# ipro7 register map
Vendor: intelpro; Series: BTBLE
CPU: ipro7, little endian
Registers are 32-bit, read-write, reset 0x0 unless marked. A register's access mark holds for its fields unless they carry their own. Offsets are from the block's base; [hi:lo] are bit positions; lines under a group give offsets from that group; {n}, {i} and the like mark numbered series; <NAME> marks a mode.

## M154
Base 0x3C000000
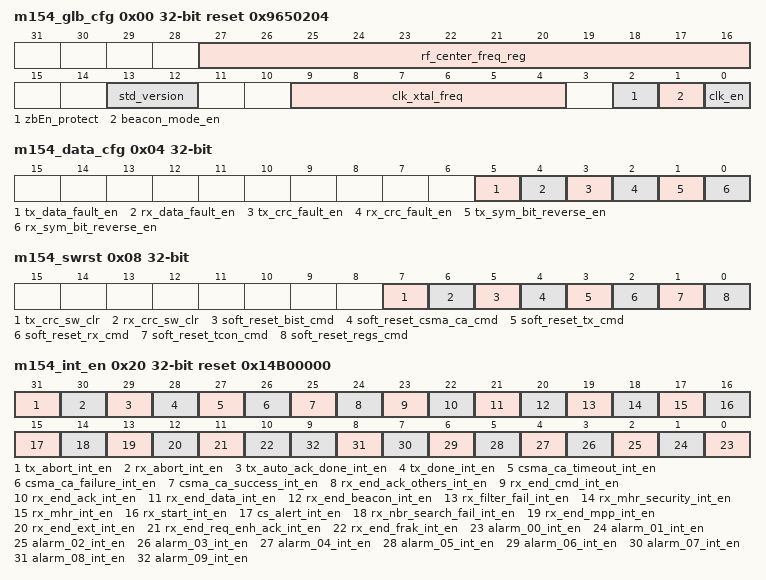
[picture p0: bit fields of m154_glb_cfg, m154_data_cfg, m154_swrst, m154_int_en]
0x00 m154_glb_cfg reset 0x9650204
  [27:16] rf_center_freq_reg — Clock frequency (MHz)
  [13:12] std_version — 0: 802.15.4-2011 and before 1: 802.15.4-2015 others: reserved
  [9:4] clk_xtal_freq — Clock frequency (MHz)
  [2] zbEn_protect — If protect, when zbEn=0, MAC enter idle state
  [1] beacon_mode_en — Beacon enable
  [0] clk_en — MAC enable
0x04 m154_data_cfg
  [5] tx_data_fault_en — Insert fault to TX data by inverting all bits
  [4] rx_data_fault_en — Insert fault to RX data by inverting all bits
  [3] tx_crc_fault_en — Insert fault to TX FCS by inverting all bits
  [2] rx_crc_fault_en — Insert fault to RX FCS by inverting all bits
  [1] tx_sym_bit_reverse_en — Swap TX symbol bit order
  [0] rx_sym_bit_reverse_en — Swap RX symbol bit order
0x08 m154_swrst
  [7] tx_crc_sw_clr — SW clear TX CRC state registers.
  [6] rx_crc_sw_clr — SW clear RX CRC state registers.
  [5] soft_reset_bist_cmd — SW reset BIST
  [4] soft_reset_csma_ca_cmd — SW reset TX CSMA-CA
  [3] soft_reset_tx_cmd — SW reset TX
  [2] soft_reset_rx_cmd — SW reset RX
  [1] soft_reset_tcon_cmd — SW reset symbol counter and timing controller
  [0] soft_reset_regs_cmd — SW reset control registers
0x0C m154_dbg_sel
  [3:0] debug_out_sel
0x10 m154_dbg_int_en
  [31:0] debug_int_raw_en
0x20 m154_int_en reset 0x14B00000
  [31] tx_abort_int_en — TX abort interrupt enable
  [30] rx_abort_int_en — RX abort interrupt enable
  [29] tx_auto_ack_done_int_en — TX auto ACK frame transmission done interrupt enable
  [28] tx_done_int_en — TX done interrupt enable
  [27] csma_ca_timeout_int_en — CSMA-CA time out interrupt enable
  [26] csma_ca_failure_int_en — CSMA-CA failure interrupt enable
  [25] csma_ca_success_int_en — CSMA-CA success interrupt enable
  [24] rx_end_ack_others_int_en — RX end of irrelevant ACK frame (to other devices) interrupt enable
  [23] rx_end_cmd_int_en — RX end of COMMAND frame interrupt enable
  [22] rx_end_ack_int_en — RX end of relevant ACK frame (to this device) interrupt enable
  [21] rx_end_data_int_en — RX end of DATA frame interrupt enable
  [20] rx_end_beacon_int_en — RX end of BEACON frame interrupt enable
  [19] rx_filter_fail_int_en — RX filtering fail interrupt enable
  [18] rx_mhr_security_int_en — RX MAC header (with security enable field as TRUE) interrupt enable
  [17] rx_mhr_int_en — RX MAC header (regardless of security field) interrupt enable
  [16] rx_start_int_en — RX start interrupt enable
  [15] cs_alert_int_en — 802.15.4 context switch alert interrupt enable
  [14] rx_nbr_search_fail_int_en — RX NBR search fail interrupt enable.
  [13] rx_end_mpp_int_en — RX end of relevant MULTI PURPOSE frame (to this device) interrupt enable
  [12] rx_end_ext_int_en — RX end of relevant EXTENDED frame (to this device) interrupt enable
  [11] rx_end_req_enh_ack_int_en — RX end of requesting Enh-Ack frame interrupt enable
  [10] rx_end_frak_int_en — RX end of relevant FRAGEMENT or FRAK frame (to this device) interrupt enable
  [n] alarm_{n:02}_int_en (n=0..9) — Alarm {n:02} interrupt enable
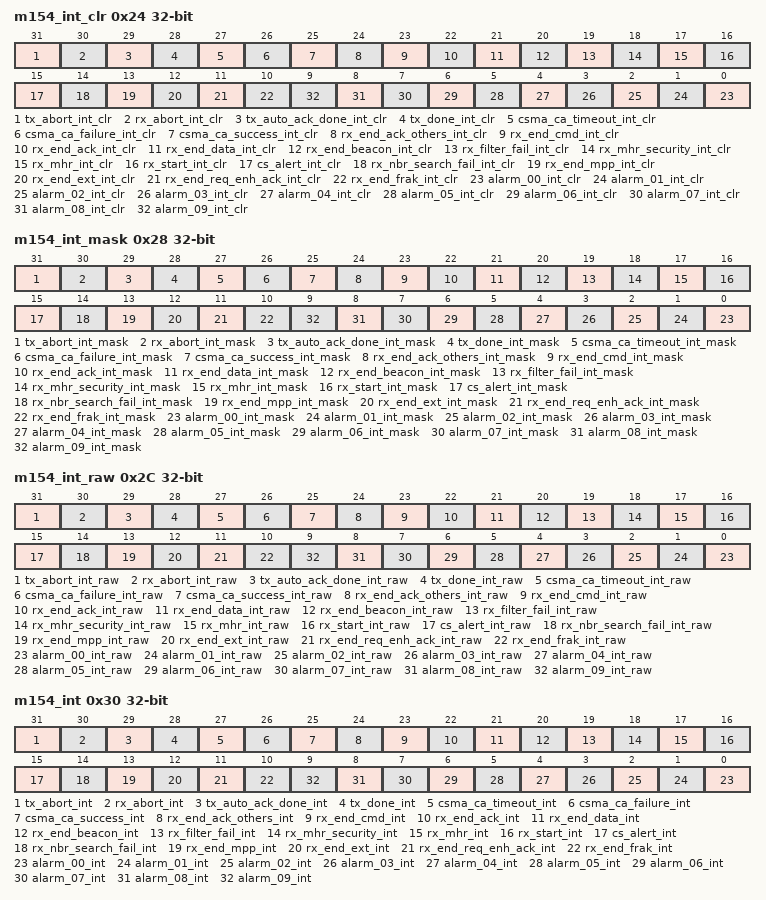
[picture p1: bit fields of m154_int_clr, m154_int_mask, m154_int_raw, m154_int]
0x24 m154_int_clr
  [31] tx_abort_int_clr — TX abort interrupt clear
  [30] rx_abort_int_clr — RX abort interrupt clear
  [29] tx_auto_ack_done_int_clr — TX auto ACK frame transmission done interrupt clear. Set to let TX FSM escape from FSM_AA_DONE
  [28] tx_done_int_clr — TX done interrupt clear. Set to let TX FSM escape from FSM_DONE
  [27] csma_ca_timeout_int_clr — CSMA-CA time out interrupt clear
  [26] csma_ca_failure_int_clr — CSMA-CA failure interrupt clear
  [25] csma_ca_success_int_clr — CSMA-CA success interrupt clear
  [24] rx_end_ack_others_int_clr — RX end of irrelevant ACK frame (to other devices) interrupt clear
  [23] rx_end_cmd_int_clr — RX end of COMMAND frame interrupt clear
  [22] rx_end_ack_int_clr — RX end of relevant ACK frame (to this device) interrupt clear
  [21] rx_end_data_int_clr — RX end of DATA frame interrupt clear
  [20] rx_end_beacon_int_clr — RX end of BEACON frame interrupt clear
  [19] rx_filter_fail_int_clr — RX filtering fail interrupt clear
  [18] rx_mhr_security_int_clr — RX MAC header (with security enable field as TRUE) interrupt clear
  [17] rx_mhr_int_clr — RX MAC header (regardless of security field) interrupt clear
  [16] rx_start_int_clr — RX start interrupt clear
  [15] cs_alert_int_clr — 802.15.4 context switch alert interrupt clear
  [14] rx_nbr_search_fail_int_clr — RX NBR search fail interrupt clear
  [13] rx_end_mpp_int_clr — RX end of relevant MULTI PURPOSE frame (to this device) interrupt clear
  [12] rx_end_ext_int_clr — RX end of relevant EXTENDED frame (to this device) interrupt clear
  [11] rx_end_req_enh_ack_int_clr — RX end of requesting Enh-Ack frame interrupt clear
  [10] rx_end_frak_int_clr — RX end of relevant FRAGEMENT or FRAK frame (to this device) interrupt clear
  [n] alarm_{n:02}_int_clr (n=0..9) — Alarm {n:02} interrupt clear
0x28 m154_int_mask
  [31] tx_abort_int_mask — TX abort interrupt mask
  [30] rx_abort_int_mask — RX abort interrupt mask
  [29] tx_auto_ack_done_int_mask — TX auto ACK frame transmission done interrupt mask
  [28] tx_done_int_mask — TX done interrupt mask
  [27] csma_ca_timeout_int_mask — CSMA-CA time out interrupt mask
  [26] csma_ca_failure_int_mask — CSMA-CA failure interrupt mask
  [25] csma_ca_success_int_mask — CSMA-CA success interrupt mask
  [24] rx_end_ack_others_int_mask — RX end of irrelevant ACK frame (to other devices) interrupt mask
  [23] rx_end_cmd_int_mask — RX end of COMMAND frame interrupt mask
  [22] rx_end_ack_int_mask — RX end of relevant ACK frame (to this device) interrupt mask
  [21] rx_end_data_int_mask — RX end of DATA frame interrupt mask
  [20] rx_end_beacon_int_mask — RX end of BEACON frame interrupt mask
  [19] rx_filter_fail_int_mask — RX filtering fail interrupt mask
  [18] rx_mhr_security_int_mask — RX MAC header (with security enable field as TRUE) interrupt mask
  [17] rx_mhr_int_mask — RX MAC header (regardless of security field) interrupt mask
  [16] rx_start_int_mask — RX start interrupt mask
  [15] cs_alert_int_mask — 802.15.4 context switch alert interrupt mask
  [14] rx_nbr_search_fail_int_mask — RX NBR search fail interrupt mask
  [13] rx_end_mpp_int_mask — RX end of relevant MULTI PURPOSE frame (to this device) interrupt mask
  [12] rx_end_ext_int_mask — RX end of relevant EXTEND frame (to this device) interrupt mask
  [11] rx_end_req_enh_ack_int_mask — RX end of requesting Enh-Ack frame interrupt mask
  [10] rx_end_frak_int_mask — RX end of relevant FRAGEMENT or FRAK frame (to this device) interrupt mask
  [n] alarm_{n:02}_int_mask (n=0..9) — Alarm {n:02} interrupt mask
0x2C m154_int_raw reset not defined
  [31] tx_abort_int_raw ro — TX abort interrupt raw status
  [30] rx_abort_int_raw ro — RX abort interrupt raw status
  [29] tx_auto_ack_done_int_raw ro — TX auto ACK frame transmission done interrupt raw status
  [28] tx_done_int_raw ro — TX done interrupt raw status
  [27] csma_ca_timeout_int_raw ro — CSMA-CA time out interrupt raw status
  [26] csma_ca_failure_int_raw ro — CSMA-CA failure interrupt raw status
  [25] csma_ca_success_int_raw ro — CSMA-CA success interrupt raw status
  [24] rx_end_ack_others_int_raw ro — RX end of irrelevant ACK frame (to other devices) interrupt raw status
  [23] rx_end_cmd_int_raw ro — RX end of COMMAND frame interrupt raw status
  [22] rx_end_ack_int_raw ro — RX end of relevant ACK frame (to this device) interrupt raw status
  [21] rx_end_data_int_raw ro — RX end of DATA frame interrupt raw status
  [20] rx_end_beacon_int_raw ro — RX end of BEACON frame interrupt raw status
  [19] rx_filter_fail_int_raw ro — RX filtering fail interrupt raw status
  [18] rx_mhr_security_int_raw ro — RX MAC header (with security enable field as TRUE) interrupt raw status (Not for ACK frames)
  [17] rx_mhr_int_raw ro — RX MAC header (regardless of security field) interrupt raw status (Not for ACK frames)
  [16] rx_start_int_raw ro — RX start interrupt raw status
  [15] cs_alert_int_raw ro — 802.15.4 context switch alert interrupt raw status. To detect if 802.15.4 MAC is doing TX/RX when zbEn=0
  [14] rx_nbr_search_fail_int_raw ro — RX NBR search fail interrupt raw status. This is an indication that data request command frame is received but source address is not found in NBR list.
  [13] rx_end_mpp_int_raw ro — RX end of relevant MULTI PURPOSE frame (to this device) interrupt raw status
  [12] rx_end_ext_int_raw ro — RX end of relevant EXTENDED frame (to this device) interrupt raw status
  [11] rx_end_req_enh_ack_int_raw ro — RX end of requesting Enh-Ack frame interrupt status
  [10] rx_end_frak_int_raw ro — RX end of relevant FRAGEMENT or FRAK frame (to this device) interrupt raw status
  [n] alarm_{n:02}_int_raw ro (n=0..9) — Alarm {n:02} interrupt raw status
0x30 m154_int reset not defined
  [31] tx_abort_int ro — TX abort interrupt after masking
  [30] rx_abort_int ro — RX abort interrupt after masking
  [29] tx_auto_ack_done_int ro — TX auto ACK frame transmission done interrupt after masking
  [28] tx_done_int ro — TX done interrupt after masking
  [27] csma_ca_timeout_int ro — CSMA-CA time out interrupt after masking
  [26] csma_ca_failure_int ro — CSMA-CA failure interrupt after masking
  [25] csma_ca_success_int ro — CSMA-CA success interrupt after masking
  [24] rx_end_ack_others_int ro — RX end of irrelevant ACK frame (to other devices) interrupt after masking
  [23] rx_end_cmd_int ro — RX end of COMMAND frame interrupt after masking
  [22] rx_end_ack_int ro — RX end of relevant ACK frame (to this device) interrupt after masking
  [21] rx_end_data_int ro — RX end of DATA frame interrupt after masking
  [20] rx_end_beacon_int ro — RX end of BEACON frame interrupt after masking
  [19] rx_filter_fail_int ro — RX filtering fail interrupt after masking
  [18] rx_mhr_security_int ro — RX MAC header (with security enable field as TRUE) interrupt after masking (Not for ACK frames)
  [17] rx_mhr_int ro — RX MAC header (regardless of security field) interrupt after masking (Not for ACK frames)
  [16] rx_start_int ro — RX start interrupt after masking
  [15] cs_alert_int ro — 802.15.4 context switch alert interrupt after masking
  [14] rx_nbr_search_fail_int ro — RX NBR search fail interrupt after masking. This is an indication that data request command frame is received but source address is not found in NBR list.
  [13] rx_end_mpp_int ro — RX end of relevant MULTI PURPOSE frame (to this device) interrupt after masking.
  [12] rx_end_ext_int ro — RX end of relevant EXTENDED frame (to this device) interrupt after masking.
  [11] rx_end_req_enh_ack_int ro — RX end of requesting Enh-Ack frame interrupt masking
  [10] rx_end_frak_int ro — RX end of relevant FRAGEMENT or FRAK frame (to this device) interrupt after masking.
  [n] alarm_{n:02}_int ro (n=0..9) — Alarm {n:02} interrupt after masking
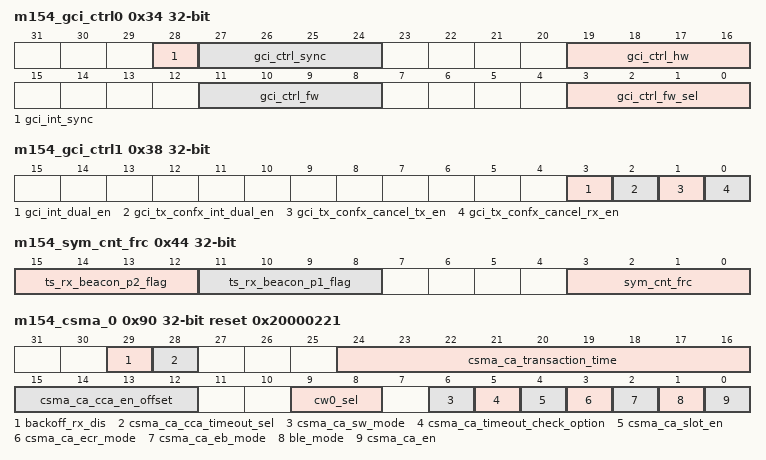
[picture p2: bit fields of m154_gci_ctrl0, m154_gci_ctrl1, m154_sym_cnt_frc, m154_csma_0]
0x34 m154_gci_ctrl0 (reset mask 0xE0F0FFFF)
  [28] gci_int_sync ro — Interrupt from GCI
  [27:24] gci_ctrl_sync ro — Control signals from GCI
  [19:16] gci_ctrl_hw ro — Hardware mode control signals to GCI [2] RX in process [1] STATUS [0] RF_ACTIVE
  [11:8] gci_ctrl_fw — Firmware mode control signals to GCI
  [3:0] gci_ctrl_fw_sel — Select control signals to GCI. 0: 2_gci_ctrl_hw, 1: 2_gci_ctrl_fw
0x38 m154_gci_ctrl1
  [3] gci_int_dual_en — Assert gci_int_raw by both edges of f_gci_int_sync
  [2] gci_tx_confx_int_dual_en — Assert gci_tx_confx_int_raw by both edges of f_gci_ctrl_sync[0]
  [1] gci_tx_confx_cancel_tx_en — Cancel TX by f_gci_ctrl_sync[0]
  [0] gci_tx_confx_cancel_rx_en — Cancel RX by f_gci_ctrl_sync[0]
0x40 m154_sym_cnt reset not defined
  [31:0] sym_cnt ro — Free run symbol counter. Increase every 16 us.
0x44 m154_sym_cnt_frc (reset mask 0xFFFF00F0)
  [15:12] ts_rx_beacon_p2_flag ro — Flags for RX BEACON frame at ts_rx_beacon_p2 bit 0: PAN ID == rx_pan_id_1st && rx_stack_1st_en == 1 bit 1: PAN ID == 16'hFFFF && rx_stack_1st_en == 1 bit 2: PAN ID == rx_pan_id_2nd && rx_stack_2nd_en == 1 bit 3: PAN ID == 16'hFFFF && rx_stack_2nd_en == 1
  [11:8] ts_rx_beacon_p1_flag ro — Flags for RX BEACON frame at ts_rx_beacon_p1 bit 0: PAN ID == rx_pan_id_1st && rx_stack_1st_en == 1 bit 1: PAN ID == 16'hFFFF && rx_stack_1st_en == 1 bit 2: PAN ID == rx_pan_id_2nd && rx_stack_2nd_en == 1 bit 3: PAN ID == 16'hFFFF && rx_stack_2nd_en == 1
  [3:0] sym_cnt_frc ro — Fractional part of free run symbol counter. Increase every 1 us.
0x48 m154_ts_rx_beacon_p1 reset not defined
  [31:0] ts_rx_beacon_p1 ro — Timestamp(us) at the latest RX BEACON frame
0x4C m154_ts_rx_beacon_p2 reset not defined
  [31:0] ts_rx_beacon_p2 ro — Timestamp(us) at RX BEACON frame prior to the latest RX BEACON frame
0x50 m154_ts_rx_start reset not defined
  [31:0] ts_rx_start ro — Timestamp(us) at start of receiving
0x54 m154_ts_rx_end reset not defined
  [31:0] ts_rx_end ro — Timestamp(us) at end of receiving
0x58 m154_ts_csma_ca_start reset not defined
  [31:0] ts_csma_ca_start ro — Timestamp(us) at start of CSMA-CA
0x5C m154_ts_tx_beacon reset not defined
  [31:0] ts_tx_beacon ro — Timestamp(us) at the latest TX BEACON frame
0x60 m154_ts_tx_end reset not defined
  [31:0] ts_tx_end ro — Timestamp(us) at end of transmitting
0x64 m154_alarm_00_target reset 0x10
  [31:0] alarm_00_target — Alarm 00 target value of symbol counter. Interrupt asserted @this symbol time
0x68 m154_alarm_01_target reset 0x20
  [31:0] alarm_01_target — Alarm 01 target value of symbol counter. Interrupt asserted @this symbol time
0x6C m154_alarm_02_target reset 0x30
  [31:0] alarm_02_target — Alarm 02 target value of symbol counter. Interrupt asserted @this symbol time
0x70 m154_alarm_03_target reset 0x40
  [31:0] alarm_03_target — Alarm 03 target value of symbol counter. Interrupt asserted @this symbol time
0x74 m154_alarm_04_target reset 0x50
  [31:0] alarm_04_target — Alarm 04 target value of symbol counter. Interrupt asserted @this symbol time
0x78 m154_alarm_05_target reset 0x60
  [31:0] alarm_05_target — Alarm 05 target value of symbol counter. Interrupt asserted @this symbol time
0x7C m154_alarm_06_target reset 0x70
  [31:0] alarm_06_target — Alarm 06 target value of symbol counter. Interrupt asserted @this symbol time
0x80 m154_alarm_07_target reset 0x80
  [31:0] alarm_07_target — Alarm 07 target value of symbol counter. Interrupt asserted @this symbol time
0x84 m154_alarm_08_target reset 0x90
  [31:0] alarm_08_target — Alarm 08 target value of symbol counter. Interrupt asserted @this symbol time
0x88 m154_alarm_09_target reset 0xA0
  [31:0] alarm_09_target — Alarm 09 target value of symbol counter. Interrupt asserted @this symbol time
0x90 m154_csma_0 reset 0x20000221
  [29] backoff_rx_dis — Disable packet receipt in Backoff state.
  [28] csma_ca_cca_timeout_sel — CCA timeout selection: 20 or 40 symbol periods. If timeout, csma_ca_timeout_int_raw = 1
  [24:16] csma_ca_transaction_time — Transaction time (SHR+PHR+PSDU). If need ACK, include macAckWaitDuration (54 symbol periods)
  [15:12] csma_ca_cca_en_offset — CCA trigger 8*N us earlier than next backoff boundary
  [9:8] cw0_sel — Initial CW (Contention Window) length setting. Set 1 for Japanese 950MHz band. Set 2 for others
  [6] csma_ca_sw_mode
  [5] csma_ca_timeout_check_option — CSMA-CA timeout check option 0: Detect PHY CCA no respond only. When csma_ca_timeout_int_raw = 1, it's CCA timeout 1: Detect PHY CCA no respond or TX cannot complete in CAP. When csma_ca_timeout_int_raw = 1, FW need to check csma_ca_fsm_curr : st_timeout_cca (CCA timeout) or st_timeout (TX cannot complete in CAP)
  [4] csma_ca_slot_en — Slotted enable
  [3] csma_ca_ecr_mode — Enhanced collision resolution mode
  [2] csma_ca_eb_mode — Enhanced backoff mode
  [1] ble_mode — Battery life extension mode
  [0] csma_ca_en — CSMA-CA is required before transmission
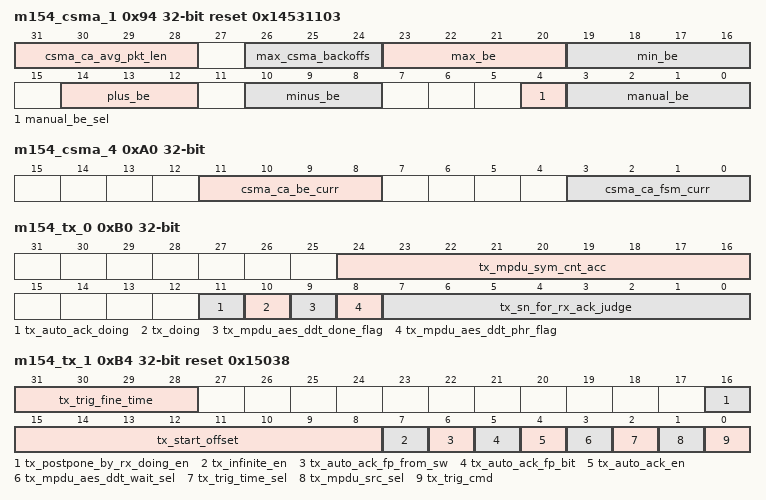
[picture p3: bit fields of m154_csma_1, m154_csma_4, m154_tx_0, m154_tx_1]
0x94 m154_csma_1 reset 0x14531103
  [31:28] csma_ca_avg_pkt_len — Average packet length = SHR(5B) + PHR(1B) + Average pay load (5~127 bytes)
  [26:24] max_csma_backoffs — Max number of CSMA-CA backoff before declaring a channel access failure. Range=0~5
  [23:20] max_be — Max value of CSMA-CA BE (Backoff Exponent). Range=3~8
  [19:16] min_be — Min value of CSMA-CA BE (Backoff Exponent). Range=0~max_be
  [14:12] plus_be — BE is increased by plus_be after failure of CSMA-CA @csma_ca_ecr_mode = 1
  [10:8] minus_be — BE is decreased by minus_be after success of CSMA-CA @csma_ca_ecr_mode = 1
  [4] manual_be_sel — BE manual enable
  [3:0] manual_be — BE fixed this value @manual_be_sel = 1 Used to init preBE @csma_ca_ecr_mode = 1
0x98 m154_csma_2
  [31:0] csma_ca_cap_end — Symbol time of CAP end
0x9C m154_csma_3
  [31:0] csma_ca_ble_period_end — Symbol time of BLE (Battery Life Extension) period end
0xA0 m154_csma_4 (reset mask 0xFFFFF0F0)
  [11:8] csma_ca_be_curr ro — Current BE value. FW need to check after finishing CSMA-CA for ECR mode
  [3:0] csma_ca_fsm_curr ro — CSMA-CA FSM 0: st_idle. 1: st_load_setting1. Load random generator seed 2: st_load_setting2. Generate random data 3: st_timeout_check. Check sufficient time to transmit 4: st_bp_delay. BP (Backoff Period) random delay 5: st_cca1. Perform 1st CCA 6: st_cca2. Perform 2nd CCA 7: st_cca3. Perform 3rd CCA 8: st_failure_check. Check NB value. 9: st_timeout_cca. Interrupt timeout 10: st_success. Interrupt success 11: st_failure. Interrupt fail 12: st_timeout. Interrupt timeout
0xB0 m154_tx_0 (reset mask 0xFE00F000)
  [24:16] tx_mpdu_sym_cnt_acc ro — Symbol sent count of the current frame
  [11] tx_auto_ack_doing ro — TX auto ACK in-progress (wait SIFS, send MAC frame)
  [10] tx_doing ro — TX transmission in-progress (wait AES TX DDT, run CSMA-CA, wait BP boundary, wait PHY on, send MAC frame)
  [9] tx_mpdu_aes_ddt_done_flag ro — AES TX DDT done
  [8] tx_mpdu_aes_ddt_phr_flag ro — AES TX DDT tx_phr written
  [7:0] tx_sn_for_rx_ack_judge ro — SN (Sequence Number) of data/command frame
0xB4 m154_tx_1 reset 0x15038
  [31:28] tx_trig_fine_time — If csma_ca_en = 0, the time preamble is transmitted. If csma_ca_en = 1, TX delay fine time(0~15 us) after tx_trig_cmd = 1.
  [16] tx_postpone_by_rx_doing_en — Wait rx_doing = 0 before TX start
  [15:8] tx_start_offset — PHY/RF warm-up time (us)
  [7] tx_infinite_en — Continuus TX with PRBS15 pattern till this bit is reset to 0 by SW. PHR field of TX packet will be 0 if this bit is set to 1.
  [6] tx_auto_ack_fp_from_sw — If this bit is set to 1, frame pending bit in TX Auto Ack frame is equal to tx_auto_ack_fp_bit. Otherwise, frame pending bit in TX Auto Ack frame is determined by result of NBR search.
  [5] tx_auto_ack_fp_bit — Frame Pending bit when TX auto ACK is enabled. If enable, Frame Pending bit is set to 1 when Rx Frame Type == 3'b011 and Command Frame Identifier == 8'h4, set to 0 for other cases
  [4] tx_auto_ack_en — Auto ACK enable
  [3] tx_mpdu_aes_ddt_wait_sel — Wait tx_mpdu_aes_ddt_done @ tx_mpdu_src_sel = 1 0: TX trigger after AES TX DDT writes PHR 1: TX trigger after tx_mpdu_aes_ddt_done
  [2] tx_trig_time_sel — TX trigger time @ tx_trg_cmd = 1 If tx_mpdu_src_sel = 0 0: immediately 1: after sym_cnt exceeds tx_trig_time If tx_mpdu_src_sel = 1 && tx_mpdu_aes_ddt_wait_sel = 0 0: after AES TX DDT writes PHR 1: after AES TX DDT writes PHR and sym_cnt exceeds tx_trig_time If tx_mpdu_src_sel = 1 && tx_mpdu_aes_ddt_wait_sel = 1 0: after AES TX DDT is done 1: after AES TX DDT is done and sym_cnt exceeds tx_trig_time
  [1] tx_mpdu_src_sel — TX MPDU source. 0: FW (AHB), 1: DDT (internal)
  [0] tx_trig_cmd — TX start
0xB8 m154_tx_2
  [31:0] tx_trig_time — If csma_ca_en = 0, the time preamble is transmitted. If csma_ca_en = 1, TX delay time (unit: 16us) after tx_trig_cmd = 1
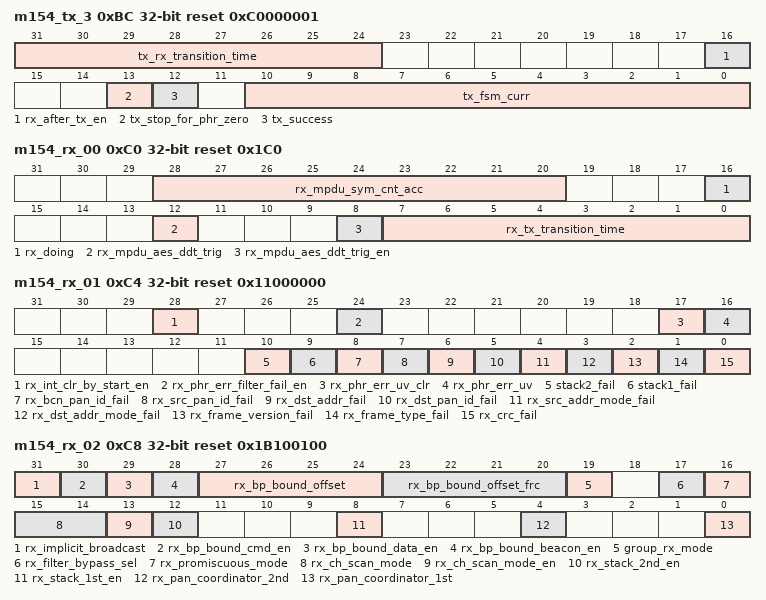
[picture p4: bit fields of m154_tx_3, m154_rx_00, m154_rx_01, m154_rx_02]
0xBC m154_tx_3 reset 0xC0000001 (reset mask 0xFFFFC800)
  [31:24] tx_rx_transition_time
  [16] rx_after_tx_en — Turn on Rx tx_rx_transition_time after TX is finished.
  [13] tx_stop_for_phr_zero ro — TX stopped due to PHR is zero.
  [12] tx_success ro — TX successfully .
  [10:0] tx_fsm_curr ro — TX FSM = {AA_DONE, DONE, SEND, WAIT, FAIL, CSMA_CA, TRIGGER, IDLE}
0xC0 m154_rx_00 reset 0x1C0 (reset mask 0xE00EEFFF)
  [28:20] rx_mpdu_sym_cnt_acc ro — Symbol number received for the current frame
  [16] rx_doing ro — RX frame reception in progress
  [12] rx_mpdu_aes_ddt_trig ro — MAC RX is waiting for AES RX DDT to be completed
  [8] rx_mpdu_aes_ddt_trig_en — Enable to issue rx_mpdu_aes_ddt_trig after receiving MAC BEACON/DATA/COMMAND frames
  [7:0] rx_tx_transition_time — Interval between RX de-assertion and following TX assertion. To allow RF/PHY complete power sequence
0xC4 m154_rx_01 reset 0x11000000 (reset mask 0xFFFEF800)
  [28] rx_int_clr_by_start_en — Enable to clear all RX related interrupts @RX start
  [24] rx_phr_err_filter_fail_en — Enable rx_phr_err_uv to trigger rx_filter_fail_int_raw
  [17] rx_phr_err_uv_clr — Clear rx_phr_err_uv
  [16] rx_phr_err_uv ro — PHY stop sending symbol to MAC RX when rx_mpdu_sym_cnt_acc[7:1] < PHR rx_phr Possible reason: Received rx_phr corrupted ; RX symbol missed ; TX abnormally stopped Clear this bit to 0 by writing rx_phr_err_uv_clr or rx_filter_fail_int_clr
  [10] stack2_fail ro — stack 2 address or pan ID fail
  [9] stack1_fail ro — stack 1 address or pan ID fail
  [8] rx_bcn_pan_id_fail ro — PAN ID in beacon frame is NOT valid
  [7] rx_src_pan_id_fail ro — Source PAN ID is NOT valid
  [6] rx_dst_addr_fail ro — Destination address is NOT valid
  [5] rx_dst_pan_id_fail ro — Destination PAN ID is NOT valid
  [4] rx_src_addr_mode_fail ro — Source addressing mode is reserved
  [3] rx_dst_addr_mode_fail ro — Destination addressing mode is reserved
  [2] rx_frame_version_fail ro — Frame version is reserved
  [1] rx_frame_type_fail ro — Frame type is reserved
  [0] rx_crc_fail ro — RX FCS field is NOT matched with HW CRC result
0xC8 m154_rx_02 reset 0x1B100100
  [31] rx_implicit_broadcast — Set 1 to support implict broadcast frame receipt.
  [30] rx_bp_bound_cmd_en — Sync backoff period boundary with RX COMMAND frames when beacon_mode_en = 1
  [29] rx_bp_bound_data_en — Sync backoff period boundary with RX DATA frames when beacon_mode_en = 1
  [28] rx_bp_bound_beacon_en — Sync backoff period boundary with RX BEACON frames when beacon_mode_en = 1
  [27:24] rx_bp_bound_offset — Backoff period boundary (rx_bp_bound_offset + rx_bp_bound_offset_frc * 1/16) symbols earlier than PHY sends MAC BEACON frame to MAC RX
  [23:20] rx_bp_bound_offset_frc — Backoff period boundary (rx_bp_bound_offset + rx_bp_bound_offset_frc * 1/16) symbols earlier than PHY sends MAC BEACON frame to MAC RX
  [19] group_rx_mode — Accespts frames with EUI-64 group address
  [17] rx_filter_bypass_sel — MAC accepts all frames received from PHY
  [16] rx_promiscuous_mode — MAC accepts all frames received from PHY (Required to pass filtering, CRC)
  [15:14] rx_ch_scan_mode — 2'b00: ED Channel Scan. Discard all frames received. 2'b01 :Active or Passive Channel Scan. Only Beacon frames are accepted. 2'b10: Orphan Channel Scan. Only Coordinator Realignment command frame is accepted. 2'b11: RIT Channel Scan. Only RIT DATA Request command frames are accepted.
  [13] rx_ch_scan_mode_en — 0: Normal RX 1: Channel scan
  [12] rx_stack_2nd_en — 2nd stack enable
  [8] rx_stack_1st_en — 1st stack enable
  [4] rx_pan_coordinator_2nd — Device is used as a PAN Coordinator in 2nd stack
  [0] rx_pan_coordinator_1st — Device is used as a PAN Coordinator in 1st stack
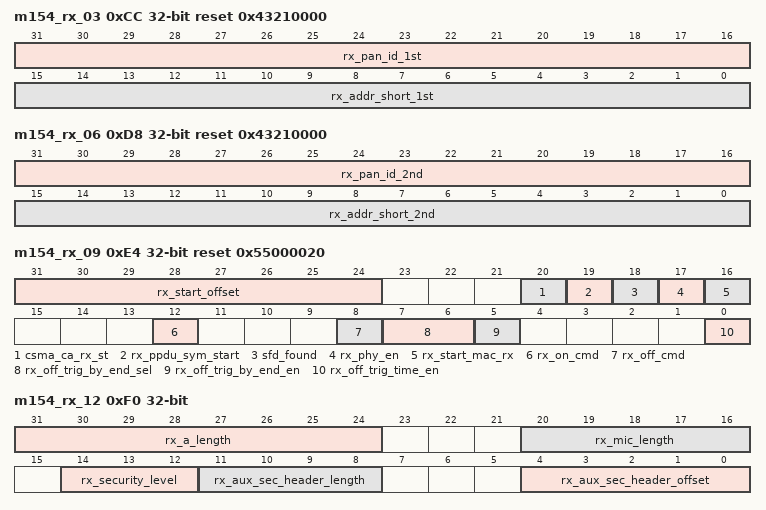
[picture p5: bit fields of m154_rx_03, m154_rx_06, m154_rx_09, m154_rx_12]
0xCC m154_rx_03 reset 0x43210000
  [31:16] rx_pan_id_1st — PAN ID (1st stack)
  [15:0] rx_addr_short_1st — Address used to communicate in PAN (1st stack). Chosen for PAN coordinator or allocated by a coordinator during association.
0xD0 m154_rx_04 reset 0x2
  [31:0] rx_addr_extended_1st_31_00 — Extended address[31:0] assigned to the device (1st stack)
0xD4 m154_rx_05 reset 0xACDE4800
  [31:0] rx_addr_extended_1st_63_32 — Extended address[63:32] assigned to the device (1st stack)
0xD8 m154_rx_06 reset 0x43210000
  [31:16] rx_pan_id_2nd — PAN ID (2nd stack)
  [15:0] rx_addr_short_2nd — Address used to communicate in PAN (2nd stack).
0xDC m154_rx_07 reset 0x2
  [31:0] rx_addr_extended_2nd_31_00 — Extended address[31:0] assigned to the device (2nd stack)
0xE0 m154_rx_08 reset 0xACDE4800
  [31:0] rx_addr_extended_2nd_63_32 — Extended address[63:32] assigned to the device (2nd stack)
0xE4 m154_rx_09 reset 0x55000020 (reset mask 0xFFE0FFFF)
  [31:24] rx_start_offset — PHY/RF warm-up time (us)
  [20] csma_ca_rx_st ro — RX on signal driven by MAC TX CSMA-CA
  [19] rx_ppdu_sym_start ro — Indication of RX PPDU symbol receiving
  [18] sfd_found ro — RX SFD found Indication
  [17] rx_phy_en ro — RX PHY on signal driven by MAC RX
  [16] rx_start_mac_rx ro — RX RF on signal driven by MAC RX
  [12] rx_on_cmd — To assert rx_start_mac_rx to initiate RX
  [8] rx_off_cmd — To de-assert rx_start_mac_rx to disable RX
  [7:6] rx_off_trig_by_end_sel — Time (rx_off_trig_by_end_sel * 8us) between RX last symbol and rx_start de-asserted @rx_off_trig_by_end_en=1
  [5] rx_off_trig_by_end_en — Enable rx_start de-asserted by MAC HW at RX last symbol
  [0] rx_off_trig_time_en — To switch RX off when sym_cnt = rx_off_trig_time
0xE8 m154_rx_10 reset 0x100
  [31:0] rx_off_trig_time — Time to trigger RX off
0xEC m154_rx_11 reset not defined
  [31:0] rx_frame_counter ro — Frame Counter field in the Auxiliary Security Header
0xF0 m154_rx_12 (reset mask 0xE080E0)
  [31:24] rx_a_length ro — CCM data length (Byte)
  [20:16] rx_mic_length ro — CCM MIC length (Byte)
  [14:12] rx_security_level ro — Security Level field in the Auxiliary Security Header
  [11:8] rx_aux_sec_header_length ro — Auxiliary Security Header length (Byte)
  [4:0] rx_aux_sec_header_offset ro — Byte offset of the Auxiliary Security Header to the RX MPDU buffer
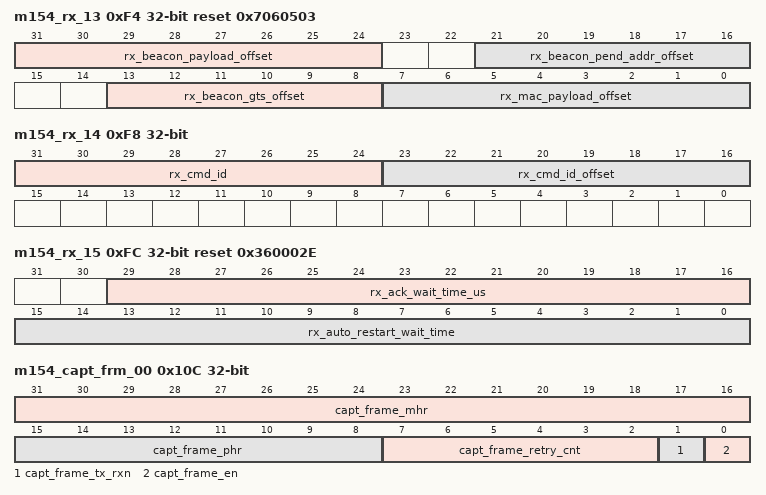
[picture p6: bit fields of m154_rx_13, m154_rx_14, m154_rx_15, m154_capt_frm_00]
0xF4 m154_rx_13 reset 0x7060503 (reset mask 0xC0C000)
  [31:24] rx_beacon_payload_offset ro — Byte offset of the BEACON frame BEACON payload to the RX MPDU buffer
  [21:16] rx_beacon_pend_addr_offset ro — Byte offset of the BEACON frame pending address to the RX MPDU buffer
  [13:8] rx_beacon_gts_offset ro — Byte offset of the BEACON frame GTS the RX MPDU buffer
  [7:0] rx_mac_payload_offset ro — Byte offset of the MAC payload to the RX MPDU buffer
0xF8 m154_rx_14 (reset mask 0xFFFF)
  [31:24] rx_cmd_id ro — COMMAND ID
  [23:16] rx_cmd_id_offset ro — Byte offset of the COMMAND frame identifier to the RX MPDU buffer
0xFC m154_rx_15 reset 0x360002E
  [29:16] rx_ack_wait_time_us — maximum wait time(us) for RX ack frame.
  [15:0] rx_auto_restart_wait_time — Interval between RX de-assertion and the next RX assertion (us)
0x100 m154_rx_16 reset 0xFFFFFFFF
  [31:0] total_frame_wait_time_us — total frame wait time (us). if bit 31 is 1, the counter will not count down..
0x104 m154_rx_17
  [0] rx_on_after_rx_ack — Turn on Rx after ACK frame is received.
0x108 m154_rsvd_01
0x10C m154_capt_frm_00
  [31:16] capt_frame_mhr — Long frame control field or least 2 bytes of MHR of target frame.
  [15:8] capt_frame_phr — PHR of target frame.
  [7:2] capt_frame_retry_cnt — Target frame retry count.
  [1] capt_frame_tx_rxn — Default is RX frame capture. Set to 1 for TX frame capture.
  [0] capt_frame_en — Enable frame capture function.
0x110 m154_sw_profile
  [31:0] sw_profile
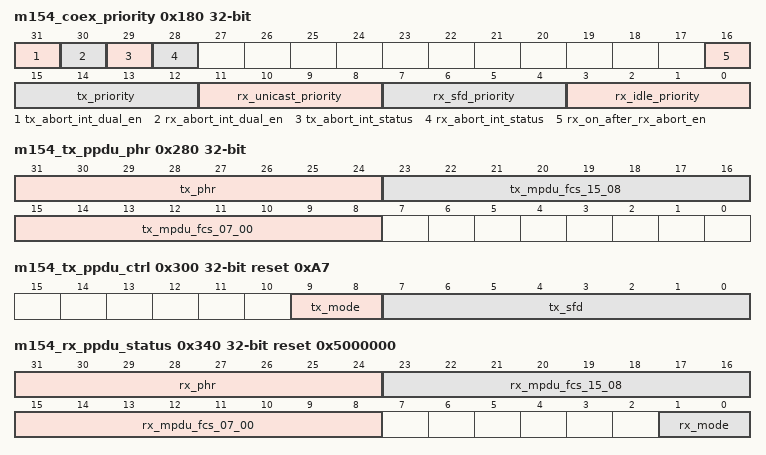
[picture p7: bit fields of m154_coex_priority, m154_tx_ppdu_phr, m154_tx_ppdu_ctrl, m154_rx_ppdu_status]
0x180 m154_coex_priority (reset mask 0xCFFFFFFF)
  [31] tx_abort_int_dual_en — Set to 1 to enable dual edge assertion of tx_abort_int. Otherwise, only rising edge assertion of tx_abort_int.
  [30] rx_abort_int_dual_en — Set to 1 to enable dual edge assertion of rx_abort_int. Otherwise, only rising edge assertion of rx_abort_int.
  [29] tx_abort_int_status ro — 1: rising edge abort, 0: falling edge abort
  [28] rx_abort_int_status ro — 1: rising edge abort, 0: falling edge abort
  [16] rx_on_after_rx_abort_en — Enable RX after falling edge of RX abort if rx_abort_en is 0.
  [15:12] tx_priority — Priority when TX MPDU is being transmitted.
  [11:8] rx_unicast_priority — Priority when RX unicast packet is being received.
  [7:4] rx_sfd_priority — Priority when RX SFD is detected
  [3:0] rx_idle_priority — Priority when Rx is IDLE
0x280 m154_tx_ppdu_phr (reset mask 0xFF)
  [31:24] tx_phr ro — TX PHY Header (TX frame length, number of bytes for TX MPDU)
  [23:16] tx_mpdu_fcs_15_08 ro — TX MPDU FCS[15: 8] (CRC)
  [15:8] tx_mpdu_fcs_07_00 ro — TX MPDU FCS[ 7: 0] (CRC)
0x300 m154_tx_ppdu_ctrl reset 0xA7
  [9:8] tx_mode — 0: 250 Kbps, 1: 500 Kbps, 2: 1 Mbps, 3: 2 Mbps
  [7:0] tx_sfd — SFD field
0x340 m154_rx_ppdu_status reset 0x5000000 (reset mask 0xFC)
  [31:24] rx_phr ro — RX PHY Header (RX frame length, number of bytes for RX MPDU)
  [23:16] rx_mpdu_fcs_15_08 ro — RX MPDU FCS[15: 8] (CRC)
  [15:8] rx_mpdu_fcs_07_00 ro — RX MPDU FCS[ 7: 0] (CRC)
  [1:0] rx_mode ro — 0: 250 Kbps, 1: 500 Kbps, 2: 1 Mbps, 3: 2 Mbps
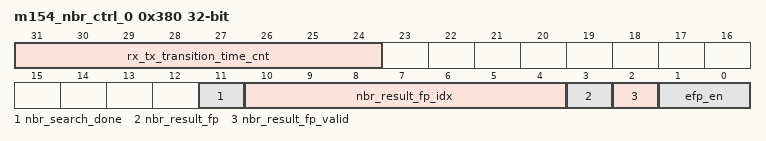
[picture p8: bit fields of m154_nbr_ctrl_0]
0x380 m154_nbr_ctrl_0 (reset mask 0xFFF003)
  [31:24] rx_tx_transition_time_cnt ro — Remaining transition time before TX RF turn on. Initial value of downcounter is rx_tx_transition_time - rx_phy_proc_time_us - tx_start_offset - 1. Note: rx_phy_proc_time_us is a BZ PHY register.
  [11] nbr_search_done ro — 0: NBR search busy 1: NBR search done
  [10:4] nbr_result_fp_idx ro — NBR table index if nbr_result_fp_valid is 1
  [3] nbr_result_fp ro — Frame pending bit of peer device in NBR table if nbr_result_fp_valid is 1.
  [2] nbr_result_fp_valid ro — 0: peer device is not in NBR table. 0: peer device is in NBR table.
  [1:0] efp_en — 0: search NBR table when data request command packet is received. 1: search NBR table when data request/data/multi-purpose packet is received. 2: search NBR table when data request/data/multi-purpose packet or any command packet is received. 3: search NBR table when data request/data/multi-purpose packet or any command packet is received.
